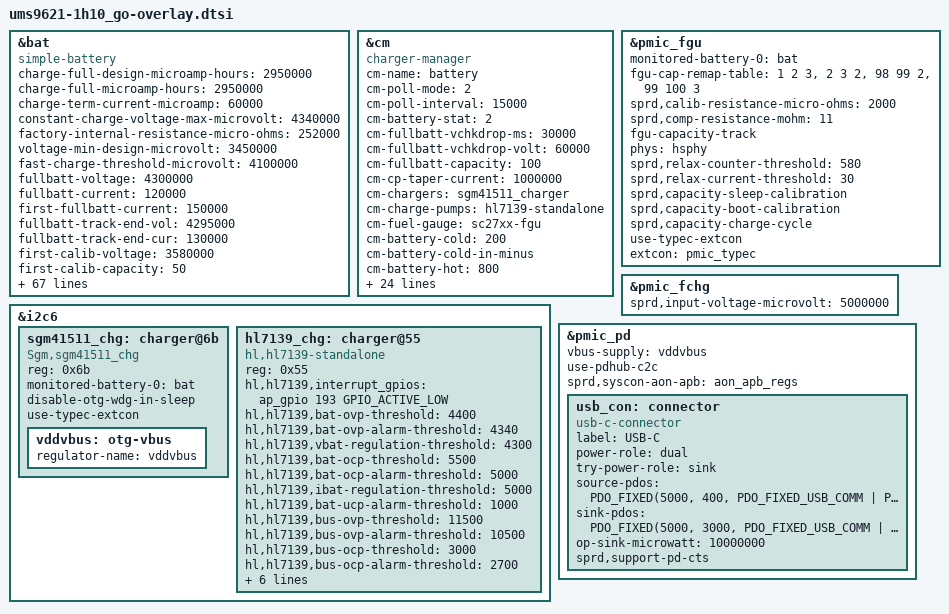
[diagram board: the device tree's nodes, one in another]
// SPDX-License-Identifier: (Licenseref-Unisoc-General-1.0 OR GPL-2.0-only)
/*
 * ums9621-1h10_go-overlay.dtsi - Unisoc platform device
 *
 * Copyright 2022 Unisoc(Shanghai) Technologies Co.Ltd
 *
 * Licensed under the Unisoc General Software License, version 1.0 (the
 * License);
 * you may not use this file except in compliance with the License.
 * You may obtain a copy of the License at
 * https://www.unisoc.com/en_us/license/UNISOC_GENERAL_LICENSE_V1.0-EN_US
 * Software distributed under the License is distributed on an "AS IS" BASIS,
 * WITHOUT WARRANTIES OF ANY KIND, either express or implied.
 * See the Unisoc General Software License, version 1.0 for more details.
 *
 * Alternatively you can use and distribute this file under the terms of the
 * GNU General Public License version 2, provided that it has to be used
 *  (including but not limited to combining, linking) with any other file under
 * the GNU General Public License version 2 on platforms that use Unisoc Chips.
 */

#include <dt-bindings/usb/pd.h>

&bat {
	compatible = "simple-battery";
	status = "okay";
	charge-full-design-microamp-hours = <2950000>;
	charge-full-microamp-hours = <2950000>;
	charge-term-current-microamp = <60000>;
	constant-charge-voltage-max-microvolt = <4340000>;
	factory-internal-resistance-micro-ohms = <252000>;
	voltage-min-design-microvolt = <3450000>;
	fast-charge-threshold-microvolt = <4100000>;
	fullbatt-voltage = <4300000>;
	fullbatt-current = <120000>;
	first-fullbatt-current = <150000>;

	fullbatt-track-end-vol = <4295000>;
	fullbatt-track-end-cur = <130000>;
	first-calib-voltage = <3580000>;
	first-calib-capacity = <50>;
	batt-ovp-threshold-microvolt = <4800000>;

	ir-cv-offset-microvolt = <100000>;
	ir-rc-micro-ohms = <20000>;
	ir-us-upper-limit-microvolt = <4500000>;

	ocv-capacity-celsius = <20>;
	ocv-capacity-table-0 = <4313000 100>, <4254000 95>, <4201000 90>,
				<4151000 85>, <4102000 80>, <4060000 75>,
				<4006000 70>, <3973000 65>, <3930000 60>,
				<3882000 55>, <3851000 50>, <3829000 45>,
				<3810000 40>, <3795000 35>, <3781000 30>,
				<3765000 25>, <3746000 20>, <3722000 15>,
				<3694000 10>, <3682000 5>, <3400000 0>;
	voltage-temp-table = <1084000 800>, <975000 850>, <868000 900>,
				  <765000 950>, <668000 1000>, <580000 1050>,
				  <501000 1100>, <430000 1150>, <369000 1200>,
				  <315000 1250>, <270000 1300>, <231000 1350>,
				  <197000 1400>, <169000 1450>, <145000 1500>,
				  <125000 1550>, <108000 1600>, <93000 1650>;
	capacity-temp-table = <45 100>, <25 100>, <10 100>, <0 95>, <(-10) 90>;
	resistance-temp-table = <45 53>, <25 100>, <10 395>, <0 567>, <(-10) 793>;
	temp-advance-fullcap-table = <50 100>, <25 100>, <10 100>, <0 100>,
		<(-10) 100>, <(-20) 100>;

	charge-sdp-current-microamp = <500000 500000>;
	charge-dcp-current-microamp = <2000000 3000000>;
	charge-cdp-current-microamp = <1500000 1500000>;
	charge-unknown-current-microamp = <1050000 1050000>;
	charge-fchg-current-microamp = <3000000 2000000>;
	charge-flash-current-microamp = <5000000 2700000>;

	cap-calib-energy-density-ocv-table = <3350000 3800000>, <4150000 4350000>;
	cap-track-energy-density-ocv-table = <3400000 3722000>;

	dcp-jeita-temp-table = <1000 1030 0 4340000>, <1150 1180 700000 4340000>,
		<1450 1420 2000000 4340000>, <1600 1570 700000 4100000>;
	sdp-jeita-temp-table = <1000 1030 0 4340000>, <1150 1180 500000 4340000>,
		<1450 1420 500000 4340000>, <1600 1570 500000 4100000>;
	cdp-jeita-temp-table = <1000 1030 0 4340000>, <1150 1180 700000 4340000>,
		<1450 1420 1500000 4340000>, <1600 1570 700000 4100000>;
	unknown-jeita-temp-table = <1000 1030 0 4340000>, <1150 1180 700000 4340000>,
		<1450 1420 1050000 4340000>, <1600 1570 700000 4100000>;
	fchg-jeita-temp-table = <1000 1030 0 4340000>, <1150 1180 700000 4340000>,
		<1450 1420 3250000 4340000>, <1600 1570 700000 4100000>;
	flash-jeita-temp-table = <1000 1020 0 4340000>, <1050 1070 500000 4340000>,
		<1120 1140 1000000 4340000>, <1160 1180 1500000 4340000>,
		<1220 1240 4500000 4340000>, <1340 1360 5000000 4340000>,
		<1370 1350 5000000 4340000>, <1400 1380 4500000 4340000>,
		<1420 1400 4250000 4340000>, <1450 1430 4000000 4340000>,
		<1600 1570 1000000 4100000>;
};

&cm {
	compatible = "charger-manager";
	status = "okay";
	cm-name = "battery";
	cm-poll-mode = <2>;
	cm-poll-interval = <15000>;
	cm-battery-stat = <2>;

	cm-fullbatt-vchkdrop-ms = <30000>;
	cm-fullbatt-vchkdrop-volt = <60000>;
	cm-fullbatt-capacity = <100>;
	/*Charge pump target charge current*/
	cm-cp-taper-current = <1000000>;

	cm-chargers = "sgm41511_charger";
	cm-charge-pumps = "hl7139-standalone";
	cm-fuel-gauge = "sc27xx-fgu";

	/* in deci centigrade */
	cm-battery-cold = <200>;
	cm-battery-cold-in-minus;
	cm-battery-hot = <800>;
	cm-battery-temp-diff = <100>;

	/* Allow charging for 6hr */
	cm-charging-max = <21600000>;
	/* recovery charging after stop charging 45min */
	cm-discharging-max = <2700000>;

	/* the interval to feed charger watchdog */
	cm-wdt-interval = <60>;

	/* drop voltage in microVolts to allow shutdown */
	cm-shutdown-voltage = <3100000>;

	/* when 99% of the time is exceeded, it will be forced to 100% */
	cm-tickle-time-out = <1500>;

	/* how much time to allow capacity change */
	cm-one-cap-time = <30>;

	cm-thermal-zone = "board-thmzone";

	/* when the safe charging voltage is exceeded, stop charging */
	cm-charge-voltage-max = <6500000>;
	cm-fast-charge-voltage-max = <10500000>;
	cm-flash-charge-voltage-max = <12000000>;
	/* drop voltage in microVolts to restart charging */
	cm-charge-voltage-drop = <700000>;
	cm-fast-charge-voltage-drop = <700000>;
	cm-flash-charge-voltage-drop = <1000000>;

	/* sprd_fchg parameter */
	sprd,support-fchg;
	sprd,support-pd-pps;
	sprd,pd-fixed-max-microwatt = <18000000>;

	monitored-battery-0 = <&bat>;
	cm-capacity-track;
	cm-keep-awake;

	phys = <&hsphy>;
	pd-extcon-enable;
	extcon = <&pmic_typec>, <&pmic_pd>;
	use-typec-extcon;

};

&i2c6 {
	#address-cells = <1>;
	#size-cells = <0>;

	status = "okay";
	sgm41511_chg: charger@6b {
		compatible = "Sgm,sgm41511_chg";
		reg = <0x6b>;
		monitored-battery-0 = <&bat>;
		disable-otg-wdg-in-sleep;
		use-typec-extcon;
		vddvbus:otg-vbus {
			regulator-name = "vddvbus";
		};
	};

	hl7139_chg: charger@55 {
		compatible = "hl,hl7139-standalone";
		reg = <0x55>;
		hl,hl7139,interrupt_gpios = <&ap_gpio 193 GPIO_ACTIVE_LOW>;

		hl,hl7139,bat-ovp-threshold = <4400>;
		hl,hl7139,bat-ovp-alarm-threshold = <4340>;
		hl,hl7139,vbat-regulation-threshold = <4300>;

		hl,hl7139,bat-ocp-threshold = <5500>;
		hl,hl7139,bat-ocp-alarm-threshold = <5000>;
		hl,hl7139,ibat-regulation-threshold = <5000>;
		hl,hl7139,bat-ucp-alarm-threshold = <1000>;

		hl,hl7139,bus-ovp-threshold = <11500>;
		hl,hl7139,bus-ovp-alarm-threshold = <10500>;
		hl,hl7139,bus-ocp-threshold = <3000>;
		hl,hl7139,bus-ocp-alarm-threshold = <2700>;

		hl,hl7139,ac-ovp-threshold = <13>;

		hl,hl7139,die-tmp-reg-threshold = <100>;

		hl,hl7139,track-ov-delta-threshold = <900>;
		hl,hl7139,track-uv-delta-threshold = <250>;

		hl,hl7139,watchdog-timer = <30000>;

		hl,hl7139,sense-resistor-mohm = <2>;
	};
};

&pmic_fgu {
	monitored-battery-0 = <&bat>;
	fgu-cap-remap-table = <1 2 3>, <2 3 2>, <98 99 2>, <99 100 3>;
	sprd,calib-resistance-micro-ohms = <2000>;
	sprd,comp-resistance-mohm = <11>;

	fgu-capacity-track;
	phys = <&hsphy>;

	sprd,relax-counter-threshold = <580>;
	sprd,relax-current-threshold = <30>;
	sprd,capacity-sleep-calibration;

	sprd,capacity-boot-calibration;
	sprd,capacity-charge-cycle;
	use-typec-extcon;
	extcon = <&pmic_typec>;
};

&pmic_fchg {
	status = "okay";
	sprd,input-voltage-microvolt = <5000000>;
};

&pmic_pd {
	status = "okay";
	vbus-supply = <&vddvbus>;
	use-pdhub-c2c;
	sprd,syscon-aon-apb = <&aon_apb_regs>;
	usb_con: connector {
		compatible = "usb-c-connector";
		label = "USB-C";
		power-role = "dual";
		try-power-role = "sink";
		source-pdos = <PDO_FIXED(5000, 400, PDO_FIXED_USB_COMM | PDO_FIXED_SUSPEND |
					 PDO_FIXED_DUAL_ROLE | PDO_FIXED_DATA_SWAP)>;
		sink-pdos = <PDO_FIXED(5000, 3000, PDO_FIXED_USB_COMM | PDO_FIXED_DUAL_ROLE |
				       PDO_FIXED_DATA_SWAP)
			     PDO_PPS_APDO(3300, 11000, 3000)>;
		op-sink-microwatt = <10000000>;

		sprd,support-pd-cts;
	};
};
